AUTOSAR XML (schema 00046)
package /ComponentTypes
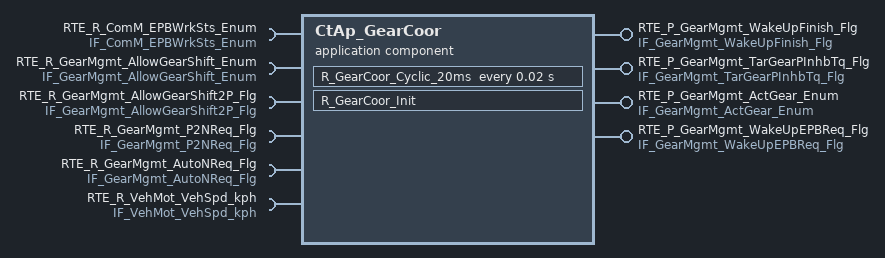
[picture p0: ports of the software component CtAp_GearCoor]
  application sw component type CtAp_GearCoor
    6 x require port:
      RTE_R_ComM_EPBWrkSts_Enum: nonqueued-receiver-com-spec{data-element=tec_ComM_EPBWrkSts_Enum, filter=data-filter-type=ALWAYS, init-value=0}, required-interface=IF_ComM_EPBWrkSts_Enum
      RTE_R_GearMgmt_AllowGearShift_Enum: nonqueued-receiver-com-spec{data-element=tec_GearMgmt_AllowGearShift_Enum, filter=data-filter-type=ALWAYS, init-value=0}, required-interface=IF_GearMgmt_AllowGearShift_Enum
      RTE_R_GearMgmt_AllowGearShift2P_Flg: nonqueued-receiver-com-spec{data-element=tec_GearMgmt_AllowGearShift2P_Flg, filter=data-filter-type=ALWAYS, init-value=0}, required-interface=IF_GearMgmt_AllowGearShift2P_Flg
      RTE_R_GearMgmt_P2NReq_Flg: nonqueued-receiver-com-spec{data-element=tec_GearMgmt_P2NReq_Flg, filter=data-filter-type=ALWAYS, init-value=0}, required-interface=IF_GearMgmt_P2NReq_Flg
      RTE_R_GearMgmt_AutoNReq_Flg: nonqueued-receiver-com-spec{data-element=tec_GearMgmt_AutoNReq_Flg, filter=data-filter-type=ALWAYS, init-value=0}, required-interface=IF_GearMgmt_AutoNReq_Flg
      RTE_R_VehMot_VehSpd_kph: nonqueued-receiver-com-spec{data-element=tec_VehMot_VehSpd_kph, filter=data-filter-type=ALWAYS, init-value=0}, required-interface=IF_VehMot_VehSpd_kph
    4 x provide port:
      RTE_P_GearMgmt_WakeUpFinish_Flg: nonqueued-sender-com-spec{data-element=tec_GearMgmt_WakeUpFinish_Flg, init-value=0}, provided-interface=IF_GearMgmt_WakeUpFinish_Flg
      RTE_P_GearMgmt_TarGearPInhbTq_Flg: nonqueued-sender-com-spec{data-element=tec_GearMgmt_TarGearPInhbTq_Flg, init-value=0}, provided-interface=IF_GearMgmt_TarGearPInhbTq_Flg
      RTE_P_GearMgmt_ActGear_Enum: nonqueued-sender-com-spec{data-element=tec_GearMgmt_ActGear_Enum, init-value=0}, provided-interface=IF_GearMgmt_ActGear_Enum
      RTE_P_GearMgmt_WakeUpEPBReq_Flg: nonqueued-sender-com-spec{data-element=tec_GearMgmt_WakeUpEPBReq_Flg, init-value=0}, provided-interface=IF_GearMgmt_WakeUpEPBReq_Flg
    behavior CtAp_GearCoor_InternalBehavior
      init event CtAp_GearCoor_InitEvent: start-on-event=R_GearCoor_Init
      timing event TMT_R_GearCoor_Cyclic_20ms: start-on-event=R_GearCoor_Cyclic_20ms, period=0.02
      runnable R_GearCoor_Init
      runnable R_GearCoor_Cyclic_20ms
        data-receive-point-by-arguments:
          6 x access:
            REC_RTE_R_ComM_EPBWrkSts_Enum_tec_ComM_EPBWrkSts_Enum: accessed-variable=RTE_R_ComM_EPBWrkSts_Enum.tec_ComM_EPBWrkSts_Enum
            REC_RTE_R_GearMgmt_AllowGearShift2P_Flg_tec_GearMgmt_AllowGearShift2P_Flg: accessed-variable=RTE_R_GearMgmt_AllowGearShift2P_Flg.tec_GearMgmt_AllowGearShift2P_Flg
            REC_RTE_R_GearMgmt_AllowGearShift_Enum_tec_GearMgmt_AllowGearShift_Enum: accessed-variable=RTE_R_GearMgmt_AllowGearShift_Enum.tec_GearMgmt_AllowGearShift_Enum
            REC_RTE_R_GearMgmt_AutoNReq_Flg_tec_GearMgmt_AutoNReq_Flg: accessed-variable=RTE_R_GearMgmt_AutoNReq_Flg.tec_GearMgmt_AutoNReq_Flg
            REC_RTE_R_GearMgmt_P2NReq_Flg_tec_GearMgmt_P2NReq_Flg: accessed-variable=RTE_R_GearMgmt_P2NReq_Flg.tec_GearMgmt_P2NReq_Flg
            REC_RTE_R_VehMot_VehSpd_kph_tec_VehMot_VehSpd_kph: accessed-variable=RTE_R_VehMot_VehSpd_kph.tec_VehMot_VehSpd_kph
        data-send-points:
          4 x access:
            SEND_RTE_P_GearMgmt_ActGear_Enum_tec_GearMgmt_ActGear_Enum: accessed-variable=RTE_P_GearMgmt_ActGear_Enum.tec_GearMgmt_ActGear_Enum
            SEND_RTE_P_GearMgmt_TarGearPInhbTq_Flg_tec_GearMgmt_TarGearPInhbTq_Flg: accessed-variable=RTE_P_GearMgmt_TarGearPInhbTq_Flg.tec_GearMgmt_TarGearPInhbTq_Flg
            SEND_RTE_P_GearMgmt_WakeUpFinish_Flg_tec_GearMgmt_WakeUpFinish_Flg: accessed-variable=RTE_P_GearMgmt_WakeUpFinish_Flg.tec_GearMgmt_WakeUpFinish_Flg
            SEND_RTE_P_GearMgmt_WakeUpEPBReq_Flg_tec_GearMgmt_WakeUpEPBReq_Flg: accessed-variable=RTE_P_GearMgmt_WakeUpEPBReq_Flg.tec_GearMgmt_WakeUpEPBReq_Flg
  swc implementation CtAp_GearCoor_Implementation: behavior=CtAp_GearCoor_InternalBehavior
    code-descriptors:
      code Default: artifact-descriptors=autosar-engineering-object=category=SWOBJ
